# STM32U366 register map
File version: 1.0
CPU: CM33 r0p1, little endian, MPU, FPU, 4 interrupt priority bits
Registers are 32-bit, read-write, reset 0x0 unless marked. A register's access mark holds for its fields unless they carry their own. Offsets are from the block's base; [hi:lo] are bit positions; {n}, {i} and the like mark numbered series; <NAME> marks a mode.

## FLASH — FLASH register block
Base 0x40022000
Same registers: SEC_FLASH 0x50022000
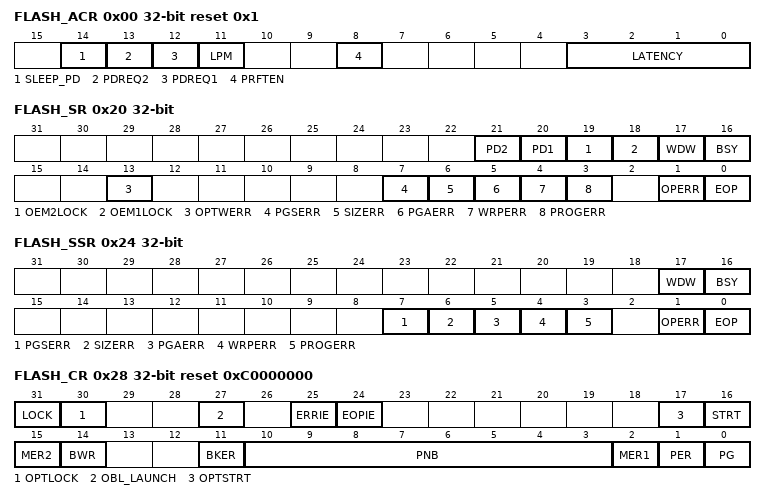
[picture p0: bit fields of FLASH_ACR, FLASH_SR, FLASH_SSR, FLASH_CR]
0x00 FLASH_ACR reset 0x1 — FLASH access control register
  [14] SLEEP_PD — Flash memory power-down mode during Sleep mode
    0=Flash in Idle mode during Sleep mode; 1=Flash in power-down mode during Sleep mode
  [13] PDREQ2 — Bank 2 power-down mode request
    0=No request for bank 2 to enter power-down mode; 1=Bank 2 requested to enter power-down mode
  [12] PDREQ1 — Bank 1 power-down mode request
    0=No request for bank 1 to enter power-down mode; 1=Bank 1 requested to enter power-down mode
  [11] LPM — Low-power read mode
    0=FLASH not in low-power read mode; 1=FLASH in low-power read mode
  [8] PRFTEN — Prefetch enable
    0=Prefetch disabled; 1=Prefetch enabled
  [3:0] LATENCY
    0=0 wait state; 1=1 wait state; 2=2 wait states; 15=15 wait states
0x08 FLASH_KEYR wo — FLASH nonsecure key register
  [31:0] KEY — Flash memory nonsecure key
0x0C FLASH_SKEYR wo — FLASH secure key register
  [31:0] KEY — Flash memory secure key
0x10 FLASH_OPTKEYR wo — FLASH option key register
  [31:0] KEY — Option-byte key
0x18 FLASH_PDKEY1R wo — FLASH bank 1 power-down key register
  [31:0] KEY1 — Bank 1 power-down key
0x1C FLASH_PDKEY2R wo — FLASH bank 2 power-down key register
  [31:0] KEY2 — Bank 2 power-down key
0x20 FLASH_SR (reset mask 0xFFF0FFFF) — FLASH nonsecure status register
  [21] PD2 ro — Bank 2 in power-down mode
  [20] PD1 ro — Bank 1 in power-down mode
  [19] OEM2LOCK ro
  [18] OEM1LOCK ro
  [17] WDW ro — Nonsecure wait data to write
  [16] BSY ro — Nonsecure busy
  [13] OPTWERR — Option write error
  [7] PGSERR — Nonsecure programming sequence error
  [6] SIZERR — Nonsecure size error
  [5] PGAERR — Nonsecure programming alignment error
  [4] WRPERR — Nonsecure write protection error
  [3] PROGERR — Nonsecure programming error
  [1] OPERR — Nonsecure operation error
  [0] EOP — Nonsecure end of operation
0x24 FLASH_SSR — FLASH secure status register
  [17] WDW ro — Secure wait data to write
  [16] BSY ro — Secure busy
  [7] PGSERR — Secure programming sequence error
  [6] SIZERR — Secure size error
  [5] PGAERR — Secure programming alignment error
  [4] WRPERR — Secure write protection error
  [3] PROGERR — Secure programming error
  [1] OPERR — Secure operation error
  [0] EOP — Secure end of operation
0x28 FLASH_CR reset 0xC0000000 — FLASH nonsecure control register
  [31] LOCK — Nonsecure lock
  [30] OPTLOCK — Option lock
  [27] OBL_LAUNCH — Option-byte loading forced
    0=Option-byte loading complete; 1=Option-byte loading requested
  [25] ERRIE — Nonsecure error interrupt enable
    0=Nonsecure OPERR error interrupt disabled; 1=Nonsecure OPERR error interrupt enabled
  [24] EOPIE — Nonsecure end of operation interrupt enable
    0=Nonsecure EOP Interrupt disabled; 1=Nonsecure EOP Interrupt enabled
  [17] OPTSTRT — Option modification start
  [16] STRT — Nonsecure start
  [15] MER2 — Nonsecure bank 2 mass erase
  [14] BWR — Nonsecure burst write programming mode
  [11] BKER — Nonsecure bank selection for page erase
    0=Bank 1 selected for nonsecure page erase; 1=Bank 2 selected for nonsecure page erase
  [10:3] PNB — Nonsecure page number selection
    0=page 0; 1=page 1; 255=page 255
  [2] MER1 — Nonsecure bank 1 mass erase
  [1] PER — Nonsecure page erase
    0=Nonsecure page erase disabled; 1=Nonsecure page erase enabled
  [0] PG — Nonsecure programming
    0=Nonsecure FLASH programming disabled; 1=Nonsecure FLASH programming enabled
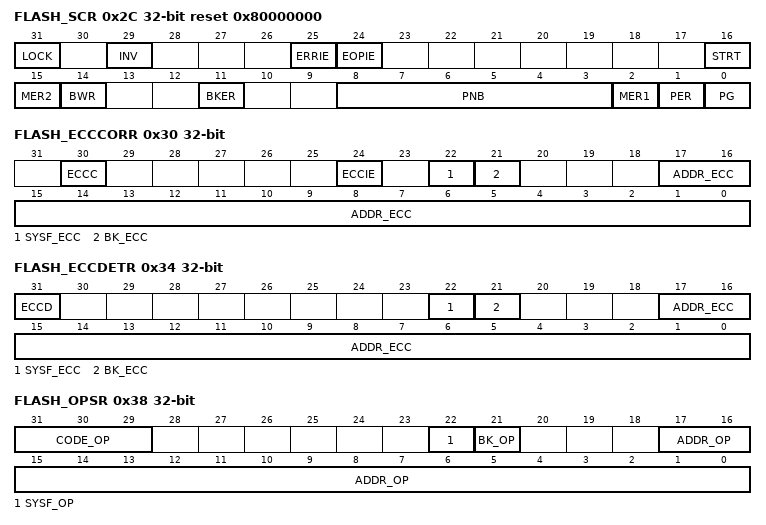
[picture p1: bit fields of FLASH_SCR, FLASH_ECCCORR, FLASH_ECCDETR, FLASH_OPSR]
0x2C FLASH_SCR reset 0x80000000 — FLASH secure control register
  [31] LOCK — Secure lock
  [29] INV — Flash memory security state invert
  [25] ERRIE — Secure error interrupt enable
    0=Secure OPERR error interrupt disabled; 1=Secure OPERR error interrupt enabled
  [24] EOPIE — Secure end of operation interrupt enable
    0=Secure EOP Interrupt disabled; 1=Secure EOP Interrupt enabled
  [16] STRT — Secure start
  [15] MER2 — Secure bank 2 mass erase
  [14] BWR — Secure burst write programming mode
  [11] BKER — Secure bank selection for page erase
    0=Bank 1 selected for secure page erase; 1=Bank 2 selected for secure page erase
  [8:3] PNB — Secure page number selection
    0=page 0; 1=page 1
  [2] MER1 — Secure bank 1 mass erase
  [1] PER — Secure page erase
    0=Secure page erase disabled; 1=Secure page erase enabled
  [0] PG — Secure programming
    0=Secure FLASH programming disabled; 1=Secure FLASH programming enabled
0x30 FLASH_ECCCORR — FLASH ECC register
  [30] ECCC — ECC correction
  [24] ECCIE — ECC correction interrupt enable
    0=ECCC interrupt disabled; 1=ECCC interrupt enabled
  [22] SYSF_ECC ro — System flash memory ECC fail
  [21] BK_ECC ro — ECC fail bank
    0=Bank 1; 1=Bank 2
  [17:0] ADDR_ECC ro — ECC fail address
0x34 FLASH_ECCDETR — FLASH ECC detection register
  [31] ECCD — ECC detection
  [22] SYSF_ECC ro — System flash memory ECC fail
  [21] BK_ECC ro — ECC fail bank
    0=Bank 1; 1=Bank 2
  [17:0] ADDR_ECC ro — ECC fail address
0x38 FLASH_OPSR ro (reset mask 0xF000000) — FLASH operation status register
  [31:29] CODE_OP — Flash memory operation code
    0=No flash operation interrupted by previous reset; 1=Single write operation interrupted; 2=Burst write operation interrupted; 3=Page erase operation interrupted; 4=Bank erase operation interrupted; 5=Mass erase operation interrupted; 6=Option change operation interrupted
  [22] SYSF_OP — Operation in system flash memory interrupted
  [21] BK_OP — Interrupted operation bank
    0=Bank 1; 1=Bank 2
  [17:0] ADDR_OP — Interrupted operation address
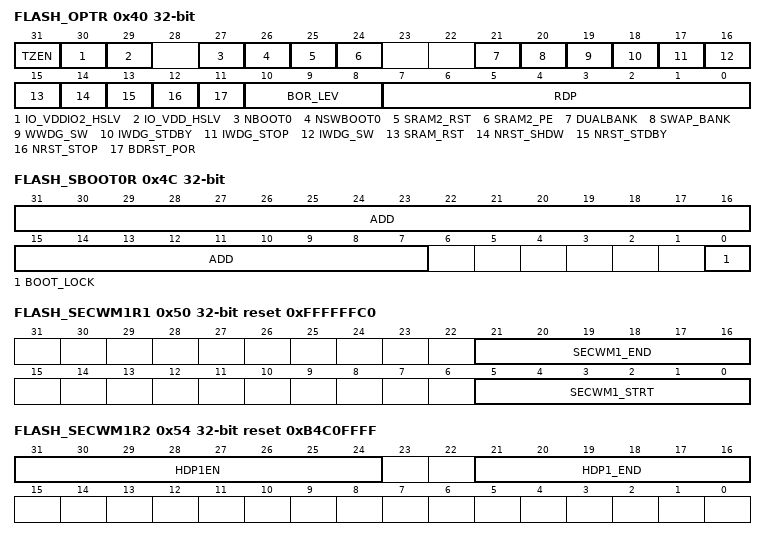
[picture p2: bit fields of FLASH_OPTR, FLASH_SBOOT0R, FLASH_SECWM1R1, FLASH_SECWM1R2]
0x40 FLASH_OPTR reset not defined — FLASH option register
  [31] TZEN — Global TrustZone security enable
    0=Global TrustZone security disabled; 1=Global TrustZone security enabled
  [30] IO_VDDIO2_HSLV — High-speed I/O at low V<sub>DDIO2</sub> voltage configuration bit
    0=High-speed I/O at low V<sub>DDIO2 </sub>voltage feature disabled (V<sub>DDIO2</sub> can exceed 2; 1=High-speed I/O at low V<sub>DDIO2 </sub>voltage feature enabled (V<sub>DDIO2</sub> remains below 2
  [29] IO_VDD_HSLV — High-speed I/O at low V<sub>DD </sub>voltage configuration bit
    0=High-speed I/O at low V<sub>DD </sub>voltage feature disabled (V<sub>DD</sub> can exceed 2; 1=High-speed I/O at low V<sub>DD </sub>voltage feature enabled (V<sub>DD</sub> remains below 2
  [27] NBOOT0 — NBOOT0 option bit
    0=NBOOT0 = 0; 1=NBOOT0 = 1
  [26] NSWBOOT0 — Software BOOT0
    0=BOOT0 taken from the option bit NBOOT0; 1=BOOT0 taken from PH3/BOOT0 pin
  [25] SRAM2_RST — SRAM2 erase when system reset
    0=SRAM2 erased when a system reset occurs; 1=SRAM2 not erased when a system reset occurs
  [24] SRAM2_PE — SRAM2 parity check enable
    0=SRAM2 parity check enabled; 1=SRAM2 parity check disabled
  [21] DUALBANK — Dual-bank configuration
    0=Single-bank FLASH with contiguous address in bank 1; 1=Dual-bank FLASH with contiguous addresses
  [20] SWAP_BANK — Swap banks
    0=Bank 1 and bank 2 addresses not swapped; 1=Bank 1 and bank 2 addresses swapped
  [19] WWDG_SW — Window watchdog selection
    0=Hardware WWDG selected; 1=Software WWDG selected
  [18] IWDG_STDBY — Independent watchdog counter freeze in Standby mode
    0=IWDG counter frozen in Standby mode; 1=IWDG counter running in Standby mode
  [17] IWDG_STOP — Independent watchdog counter freeze in Stop mode
    0=IWDG counter frozen in Stop mode; 1=IIWDG counter running in Stop mode
  [16] IWDG_SW — Independent watchdog selection
    0=Hardware IWDG selected; 1=Software IWDG selected
  [15] SRAM_RST — All SRAMs (except SRAM2 and SRAM4) erase upon system reset
    0=All SRAMs (except SRAM2 and SRAM4) erased when a system reset occurs; 1=All SRAMs (except SRAM2 and SRAM4) not erased when a system reset occurs
  [14] NRST_SHDW — Reset generation in Shutdown mode
    0=Reset generated when entering the Shutdown mode; 1=No reset generated when entering the Shutdown mode
  [13] NRST_STDBY — Reset generation in Standby mode
    0=Reset generated when entering the Standby mode; 1=No reset generate when entering the Standby mode
  [12] NRST_STOP — Reset generation in Stop mode
    0=Reset generated when entering the Stop mode; 1=No reset generated when entering the Stop mode
  [11] BDRST_POR — Backup domain reset with power-on reset
    0=The backup domain is not reset after a V<sub>DD</sub> domain brownout reset (BOR); 1=The backup domain is reset after a V<sub>DD</sub> domain brownout reset (BOR)
  [10:8] BOR_LEV — BOR reset level
    0=BOR level 0 (reset level threshold around 1; {v}=BOR level {v} (reset level threshold around 2 (v=1..4)
  [7:0] RDP — Readout protection level
    170=Level 0 (readout protection not active); 85=Level 0; 204=Level 2 (chip readout protection active)
0x44 FLASH_BOOT0R reset 0xF (reset mask 0xF) — FLASH nonsecure boot address 0 register
  [31:7] ADD — Nonsecure boot base address 0
0x48 FLASH_BOOT1R reset 0xF (reset mask 0xF) — FLASH nonsecure boot address 1 register
  [31:7] ADD — nonsecure boot address 1
0x4C FLASH_SBOOT0R reset not defined — FLASH secure boot address 0 register
  [31:7] ADD — Secure boot base address 0
  [0] BOOT_LOCK
0x50 FLASH_SECWM1R1 reset 0xFFFFFFC0 (reset mask 0xFF00FF00) — FLASH secure watermark1 register 1
  [21:16] SECWM1_END — End page of first secure area
  [5:0] SECWM1_STRT — Start page of first secure area
0x54 FLASH_SECWM1R2 reset 0xB4C0FFFF (reset mask 0xFFFF) — FLASH secure watermark1 register 2
  [31:24] HDP1EN — Hide protection first area enable
    180=No HDP area 1
  [21:16] HDP1_END — End page of first hide protection area
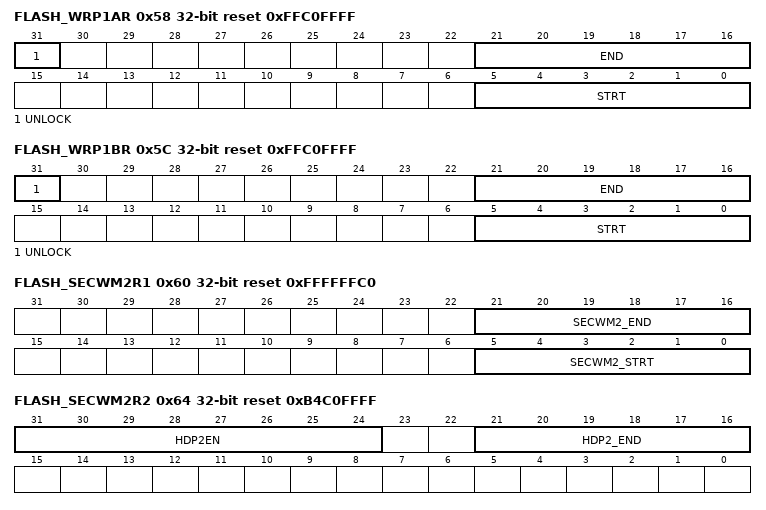
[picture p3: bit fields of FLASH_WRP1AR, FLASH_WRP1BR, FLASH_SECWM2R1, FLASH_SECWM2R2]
0x58 FLASH_WRP1AR reset 0xFFC0FFFF (reset mask 0xF00FF00) — FLASH WRP1 area A address register
  [31] UNLOCK — Bank 1 WPR first area A unlock
    0=WRP1A start and end pages locked; 1=WRP1A start and end pages unlocked
  [21:16] END — Bank 1 WPR first area A end page
  [5:0] STRT — Bank 1 WPR first area A start page
0x5C FLASH_WRP1BR reset 0xFFC0FFFF (reset mask 0xF00FF00) — FLASH WRP1 area B address register
  [31] UNLOCK — Bank 1 WPR second area B unlock
    0=WRP1B start and end pages locked; 1=WRP1B start and end pages unlocked
  [21:16] END — Bank 1 WRP second area B end page
  [5:0] STRT — Bank 1 WRP second area B start page
0x60 FLASH_SECWM2R1 reset 0xFFFFFFC0 (reset mask 0xFF00FF00) — FLASH secure watermark2 register 1
  [21:16] SECWM2_END — End page of second secure area
  [5:0] SECWM2_STRT — Start page of second secure area
0x64 FLASH_SECWM2R2 reset 0xB4C0FFFF (reset mask 0xFFFF) — FLASH secure watermark2 register 2
  [31:24] HDP2EN — Hide protection second area enable
    180=No HDP area 2
  [21:16] HDP2_END — End page of hide protection second area
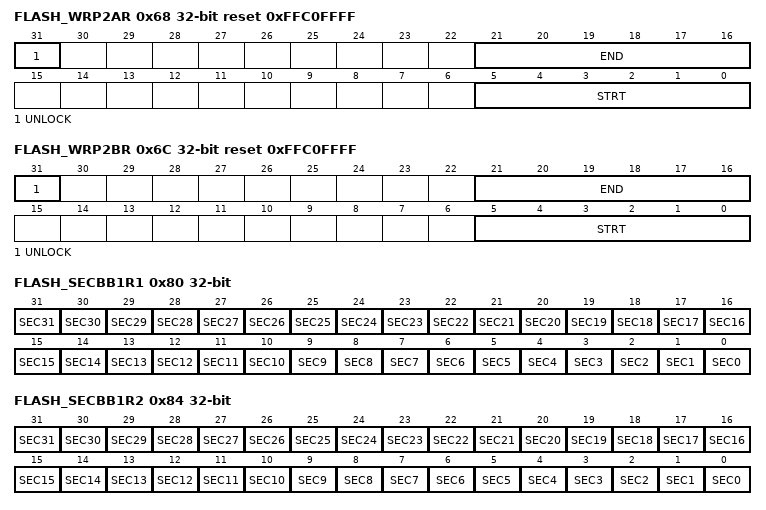
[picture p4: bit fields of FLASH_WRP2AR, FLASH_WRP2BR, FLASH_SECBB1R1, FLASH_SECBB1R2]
0x68 FLASH_WRP2AR reset 0xFFC0FFFF (reset mask 0xF00FF00) — FLASH WPR2 area A address register
  [31] UNLOCK — Bank 2 WPR first area A unlock
    0=WRP2A start and end pages locked; 1=WRP2A start and end pages unlocked
  [21:16] END — Bank 2 WPR first area A end page
  [5:0] STRT — Bank 2 WPR first area A start page
0x6C FLASH_WRP2BR reset 0xFFC0FFFF (reset mask 0xF00FF00) — FLASH WPR2 area B address register
  [31] UNLOCK — Bank 2 WPR second area B unlock
    0=WRP2B start and end pages locked; 1=WRP2B start and end pages unlocked
  [21:16] END — Bank 2 WPR second area B end page
  [5:0] STRT — Bank 2 WPR second area B start page
0x80 FLASH_SECBB1R1 — FLASH secure block based bank 1 register 1
  [n] SEC{n} (n=0..31) — Page secure/nonsecure attribution
    0=Page (32 * (1 - 1) + {n}) in bank 1 not block-based secure; 1=Page (32 * (1 - 1) + {n}) in bank 1 block-based secure
0x84 FLASH_SECBB1R2 — FLASH secure block based bank 1 register 2
  [n] SEC{n} (n=0..31) — Page secure/nonsecure attribution
    0=Page (32 * (2 - 1) + {n}) in bank 1 not block-based secure; 1=Page (32 * (2 - 1) + {n}) in bank 1 block-based secure
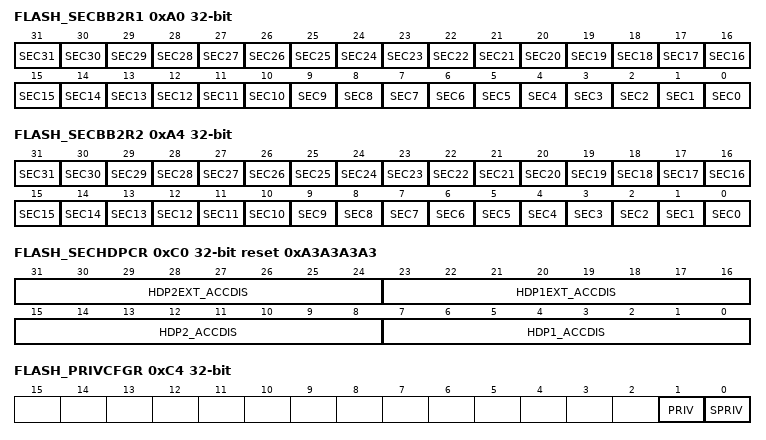
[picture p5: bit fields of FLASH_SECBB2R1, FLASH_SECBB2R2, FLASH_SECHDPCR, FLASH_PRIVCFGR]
0xA0 FLASH_SECBB2R1 — FLASH secure block based bank 2 register 1
  [n] SEC{n} (n=0..31) — Page secure/nonsecure attribution
    0=Page (32 * (1 - 1) + {n}) in bank 2 not block-based secure; 1=Page (32 * (1 - 1) + {n}) in bank 2 block-based secure
0xA4 FLASH_SECBB2R2 — FLASH secure block based bank 2 register 2
  [n] SEC{n} (n=0..31) — Page secure/nonsecure attribution
    0=Page (32 * (2 - 1) + {n}) in bank 2 not block-based secure; 1=Page (32 * (2 - 1) + {n}) in bank 2 block-based secure
0xC0 FLASH_SECHDPCR reset 0xA3A3A3A3 — FLASH secure HDP control register
  [31:24] HDP2EXT_ACCDIS — HDP2 extension area access disable
    163=Access to HDP2 extension area granted; 92=Access to HDP2 extension area and HDP2 area denied, but HDP2_EXT (inFLASH_HDPEXTR) increment allowed at any time
  [23:16] HDP1EXT_ACCDIS — HDP1 extension area access disable
    163=Access to HDP1 extension area granted; 92=Access to HDP1 extension area and HDP1 area denied, but HDP1_EXT (inFLASH_HDPEXTR) increment allowed at any time
  [15:8] HDP2_ACCDIS — HDP2 area access disable
    163=Access to HDP2 area granted
  [7:0] HDP1_ACCDIS — HDP1 area access disable
    163=Access to HDP1 area granted
0xC4 FLASH_PRIVCFGR — FLASH privilege configuration register
  [1] PRIV — Privileged protection for nonsecure registers
    0=Nonsecure FLASH registers can be read and written by privileged or unprivileged access; 1=Nonsecure FLASH registers can be read and written by privileged access only
  [0] SPRIV — Privileged protection for secure registers
    0=Secure FLASH registers can be read and written by privileged or unprivileged access; 1=Secure FLASH registers can be read and written by privileged access only
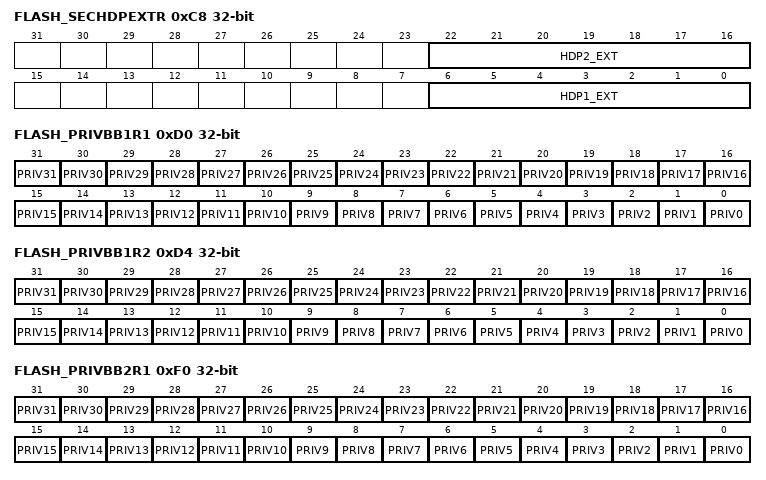
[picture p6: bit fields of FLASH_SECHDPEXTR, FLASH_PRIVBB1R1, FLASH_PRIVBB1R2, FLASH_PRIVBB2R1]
0xC8 FLASH_SECHDPEXTR — FLASH HDP extension register
  [22:16] HDP2_EXT — HDP area extension in 4-Kbyte pages in bank 2
  [6:0] HDP1_EXT — HDP area extension in 4-Kbyte pages in bank 1
0xD0 FLASH_PRIVBB1R1 — FLASH privilege block based bank 1 register 1
  [n] PRIV{n} (n=0..31) — Page privileged/unprivileged attribution
    0=Page (32 * (1 - 1) + {n}) in bank 1 accessible by unprivileged access; 1=Page (32 * (1 - 1) + {n}) in bank 1 only accessible by privileged access
0xD4 FLASH_PRIVBB1R2 — FLASH privilege block based bank 1 register 2
  [n] PRIV{n} (n=0..31) — Page privileged/unprivileged attribution
    0=Page (32 * (2 - 1) + {n}) in bank 1 accessible by unprivileged access; 1=Page (32 * (2 - 1) + {n}) in bank 1 only accessible by privileged access
0xF0 FLASH_PRIVBB2R1 — FLASH privilege block based bank 2 register 1
  [n] PRIV{n} (n=0..31) — Page privileged/unprivileged attribution
    0=Page (32 * (1 - 1) + {n}) in bank 2 accessible by unprivileged access; 1=Page (32 * (1 - 1) + {n}) in bank 2 only accessible by privileged access
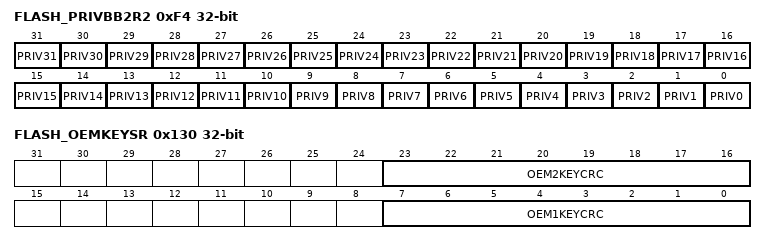
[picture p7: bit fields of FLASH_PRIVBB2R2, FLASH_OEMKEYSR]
0xF4 FLASH_PRIVBB2R2 — FLASH privilege block based bank 2 register 2
  [n] PRIV{n} (n=0..31) — Page privileged/unprivileged attribution
    0=Page (32 * (2 - 1) + {n}) in bank 2 accessible by unprivileged access; 1=Page (32 * (2 - 1) + {n}) in bank 2 only accessible by privileged access
{0x10C+4i} FLASH_OEM1KEYR{i} wo (i=1..4) — FLASH OEM1 key register {i}
  [31:0] OEM1KEY — OEM1[{32i-1}:{32i-32}] bytes key
{0x11C+4i} FLASH_OEM2KEYR{i} wo (i=1..4) — FLASH OEM2 key register {i}
  [31:0] OEM2KEY — OEM2[{32i-1}:{32i-32}] bytes key
0x130 FLASH_OEMKEYSR ro (reset mask 0xFF00FF00) — FLASH OEM key status register
  [23:16] OEM2KEYCRC — 8-bit OEM2KEY CRC
  [7:0] OEM1KEYCRC — 8-bit OEMKEY1 CRC
